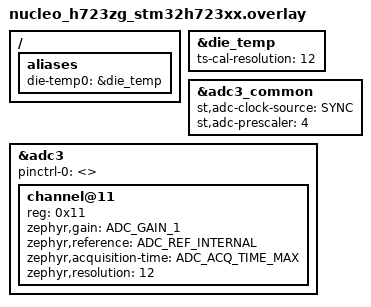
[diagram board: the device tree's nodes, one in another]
/*
 * Copyright The Zephyr Project Contributors
 *
 * SPDX-License-Identifier: Apache-2.0
 */

/ {
	aliases {
		die-temp0 = &die_temp;
	};
};

&die_temp {
	status = "okay";
	ts-cal-resolution = <12>;
};

&adc3_common {
	st,adc-clock-source = "SYNC";
	st,adc-prescaler = <4>;
	status = "okay";
};

&adc3 {
	status = "okay";
	pinctrl-0 = <>;
	pinctrl-names = "default";
	#address-cells = <1>;
	#size-cells = <0>;

	channel@11 {
		reg = <0x11>;
		zephyr,gain = "ADC_GAIN_1";
		zephyr,reference = "ADC_REF_INTERNAL";
		zephyr,acquisition-time = <ADC_ACQ_TIME_MAX>;
		zephyr,resolution = <12>;
	};
};
